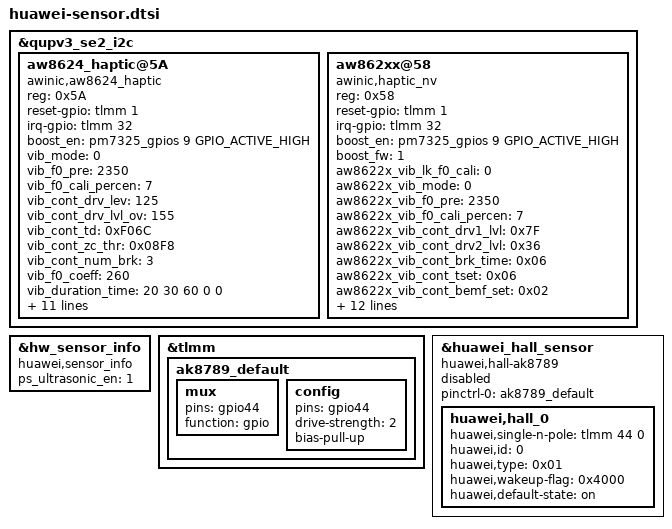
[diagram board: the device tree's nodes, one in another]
&qupv3_se2_i2c {
	status = "ok";
	#address-cells = <1>;
	#size-cells = <0>;
	aw8624_haptic@5A {
		compatible = "awinic,aw8624_haptic";
		reg = <0x5A>;
		reset-gpio = <&tlmm 1 0>;
		irq-gpio = <&tlmm 32 0>;
		boost_en = <&pm7325_gpios 9 GPIO_ACTIVE_HIGH>;
		vib_mode = < 0 >;  /*mode:  RAM mode->0; CONT mode -> 1*/
		vib_f0_pre = < 2350 >;
		vib_f0_cali_percen = < 7 >;
		vib_cont_drv_lev = < 125 >;
		vib_cont_drv_lvl_ov = < 155 >;
		vib_cont_td = < 0xF06C >;
		vib_cont_zc_thr = < 0x08F8 >;
		vib_cont_num_brk = < 3 >;
		vib_f0_coeff = < 260 >; /*Don't modify it*/
		vib_duration_time = < 20 30 60 0 0 >;
		vib_brake_cont_config = < 1 1 90 42 20 5 2 2 0 0 0  0  0  0 0 0 0 0 0   0  0  0 0 0 >;
		vib_f0_trace_parameter = < 9 5 1 15 >;
		vib_bemf_config = < 0x10 0x08 0x23 0xf8 >;
		vib_sw_brake = < 0x2c 0x08>; /*cont brake,other brake*/
		vib_wavseq = < 1 2 3 4 5 6 7 8 9 10 0 0 0 0 0 0 >; /*wavseq1-seq8 0x07-0x0E*/
		vib_wavloop = < 1 1 1 1 1 1 1 1 1 1>;/*loop1-mainloog 0x0f-0x13*/
		vib_td_brake = < 42720 42720 42720 >; /*level0  level1  level2*/
		vib_tset = < 0x11 >;
		vib_func_parameter1 = < 1 >;
		boost_power_on = < 1 >;
		status = "okay";
	};
	aw862xx@58{
		compatible = "awinic,haptic_nv";
		reg = < 0x58 >;
		reset-gpio = <&tlmm 1 0>;
		irq-gpio = <&tlmm 32 0>;
		boost_en = <&pm7325_gpios 9 GPIO_ACTIVE_HIGH>;
		boost_fw = <1>;/*1-software  0-hardware*/
		/* --------aw8622x dts info-------- */
		aw8622x_vib_lk_f0_cali = < 0 >;
		aw8622x_vib_mode = < 0 >; /* mode: RAM mode->0; CONT mode->1 */
		aw8622x_vib_f0_pre = < 2350 >;
		aw8622x_vib_f0_cali_percen = < 7 >;
		aw8622x_vib_cont_drv1_lvl = < 0x7F >;
		aw8622x_vib_cont_drv2_lvl = < 0x36 >;
		aw8622x_vib_cont_brk_time = < 0x06 >;
		aw8622x_vib_cont_tset = < 0x06 >;
		aw8622x_vib_cont_bemf_set = < 0x02 >;
		aw8622x_vib_cont_drv_width = < 0x6A >;
		aw8622x_vib_cont_wait_num = < 0x06 >;
		aw8622x_vib_cont_brk_gain = < 0x08 >;
		aw8622x_vib_cont_drv1_time = < 0x04 >;
		aw8622x_vib_cont_drv2_time = < 0x14 >;
		aw8622x_vib_cont_track_margin = < 0x12 >;
		aw8622x_vib_sine_array = < 0x05 0xB2 0xFF 0xEF >; /* SIN_H SIN_L COS_H COS_L*/
		aw8622x_vib_d2s_gain = < 0x05 >;
		aw8622x_vib_prctmode = < 0x2D 0x3E 0x3F >;
		aw8622x_vib_trig_config = < 0 0 0 1 0 2 0
					    0 0 0 1 0 2 0
					    0 0 0 1 0 2 0 >;
		aw8622x_vib_duration_time = < 20 30 60 >;
		/*aw8622x_vib_is_enabled_auto_brk;*/
		status = "okay";
	};
};

&hw_sensor_info {
	compatible = "huawei,sensor_info";
	ps_ultrasonic_en = <1>;
	status = "ok";
};

&tlmm {
	ak8789_default: ak8789_default {
		mux {
			pins = "gpio44";
			function =  "gpio";
		};
		config {
			pins = "gpio44";
			drive-strength = <2>;
			bias-pull-up;
		};
	};
};

&huawei_hall_sensor {
	compatible = "huawei,hall-ak8789";
	status = "disabled";
	pinctrl-names = "default";
	pinctrl-0 = <&ak8789_default>;

	huawei,hall_0 {
		huawei,single-n-pole = <&tlmm 44 0>;
		huawei,id = <0>;
		huawei,type = <0x01>;
		huawei,wakeup-flag = <0x4000>;
		huawei,default-state = "on";
	};
};
